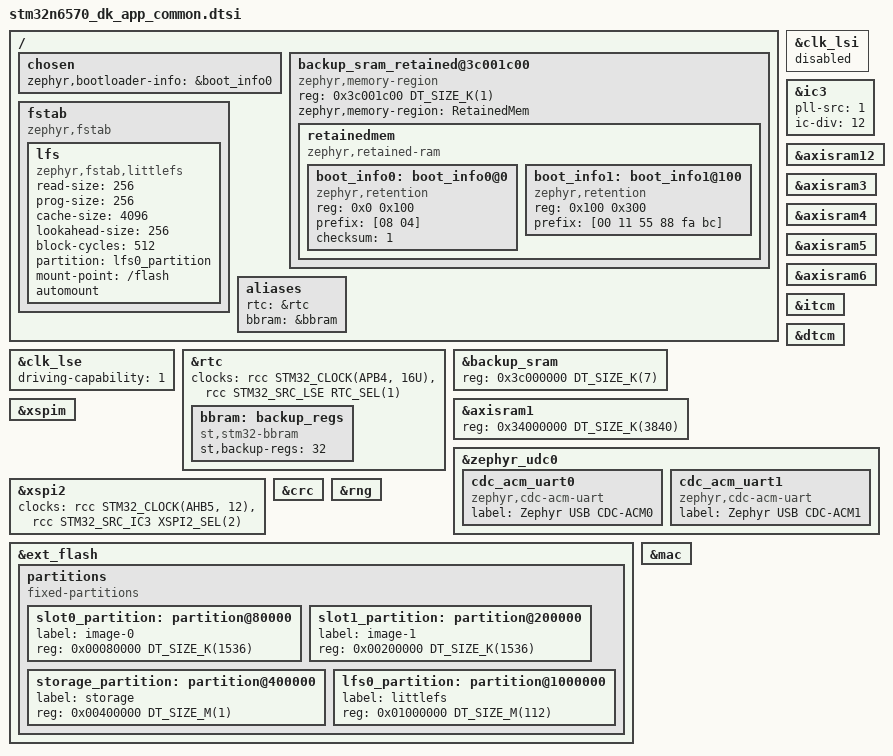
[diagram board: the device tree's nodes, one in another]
/*
 * Copyright (c) 2025 HU Inc.
 *
 * SPDX-License-Identifier: Apache-2.0
 */

#include <st/n6/stm32n657x0-sram.dtsi>

/ {
	chosen {
		zephyr,bootloader-info = &boot_info0;
	};
	/* Reserve the final 1 KiB; backup_sram owns hardware initialization. */
	backup_sram_retained@3c001c00 {
		compatible = "zephyr,memory-region", "mmio-sram";
		reg = <0x3c001c00 DT_SIZE_K(1)>;
		zephyr,memory-region = "RetainedMem";
		status = "okay";

		retainedmem {
			compatible = "zephyr,retained-ram";
			status = "okay";
			#address-cells = <1>;
			#size-cells = <1>;

			boot_info0: boot_info0@0 {
				compatible = "zephyr,retention";
				status = "okay";
				reg = <0x0 0x100>;
				prefix = [08 04];
				checksum = <1>;
			};

			boot_info1: boot_info1@100 {
				compatible = "zephyr,retention";
				status = "okay";
				reg = <0x100 0x300>;
				prefix = [00 11 55 88 fa bc];
			};
		};
	};

	fstab {
		compatible = "zephyr,fstab";
		lfs: lfs {
			compatible = "zephyr,fstab,littlefs";
			read-size=<256>;
			prog-size=<256>;
			cache-size=<4096>;
			lookahead-size=<256>;
			block-cycles=<512>;
			partition = <&lfs0_partition>;
			mount-point = "/flash";
			automount;
		};
	};

	aliases {
		rtc = &rtc;
		bbram = &bbram;
	};
};

&clk_lse {
	driving-capability = <1>;
	status = "okay";
};

&clk_lse {
	status = "okay";
};

&clk_lsi {
	status = "disabled";
};

/* Use a dedicated 200 MHz kernel clock for XSPI2 in both MCUboot and the app. */
&ic3 {
	pll-src = <1>;
	ic-div = <12>;
	status = "okay";
};

&rtc {
	clocks = <&rcc STM32_CLOCK(APB4, 16U)>,
		 <&rcc STM32_SRC_LSE RTC_SEL(1)>;
	status = "okay";

	bbram: backup_regs {
		compatible = "st,stm32-bbram";
		st,backup-regs = <32>;
		status = "okay";
	};
};

&backup_sram {
	reg = <0x3c000000 DT_SIZE_K(7)>;
	status = "okay";
};

&axisram12 {
	/* Map AXISRAM child addresses to the 0x24000000 CPU alias. */
	ranges = <0x34000000 0x24000000 DT_SIZE_K(3840)>;
};

&axisram1 {
	reg = <0x34000000 DT_SIZE_K(3840)>;
};

&axisram3 {
	status = "okay";
};

&axisram4 {
	status = "okay";
};

&axisram5 {
	status = "okay";
};

&axisram6 {
	status = "okay";
};

&itcm {
	status = "okay";
};

&dtcm {
	status = "okay";
};

&zephyr_udc0 {
	cdc_acm_uart0: cdc_acm_uart0 {
		compatible = "zephyr,cdc-acm-uart";
		label = "Zephyr USB CDC-ACM0";
	};
	cdc_acm_uart1: cdc_acm_uart1 {
		compatible = "zephyr,cdc-acm-uart";
		label = "Zephyr USB CDC-ACM1";
	};
};

&xspim {
    status = "okay";
};

&xspi2 {
	clocks = <&rcc STM32_CLOCK(AHB5, 12)>,
		 <&rcc STM32_SRC_IC3 XSPI2_SEL(2)>;
};

&crc {
    status = "okay";
};

&rng {
    status = "okay";
};

&ext_flash {
	partitions {
		compatible = "fixed-partitions";
		#address-cells = <1>;
		#size-cells = <1>;

		/delete-node/ partition@10000;
		/delete-node/ partition@210000;
		/delete-node/ partition@410000;

		slot0_partition: partition@80000 {
			label = "image-0";
			reg = <0x00080000 DT_SIZE_K(1536)>;
		};

		slot1_partition: partition@200000 {
			label = "image-1";
			reg = <0x00200000 DT_SIZE_K(1536)>;
		};

		storage_partition: partition@400000 {
			label = "storage";
			reg = <0x00400000 DT_SIZE_M(1)>;
		};

		lfs0_partition: partition@1000000 {
			label = "littlefs";
			reg = <0x01000000 DT_SIZE_M(112)>;
		};
	};
};

&mac {
	/delete-property/ nvmem-cells;
	/delete-property/ nvmem-cell-names;
};
